# nrf9230_engb_application register map
Vendor: Nordic Semiconductor; Series: nRF92; File version: 1
CPU: CM33 r0p4, little endian, MPU, FPU, 3 interrupt priority bits, 480 interrupts, 4 SAU regions
Registers are 32-bit, read-write, reset 0x0 unless marked. A register's access mark holds for its fields unless they carry their own. Offsets are from the block's base; [hi:lo] are bit positions; lines under a group give offsets from that group; 'fields as' and 'values as' point back to an identical list.

## GLOBAL_TDDCONF_NS — TDDCONF 0
Base 0xBF001000
Same registers: GLOBAL_TDDCONF_S 0xBF001000 (alternate view of GLOBAL_TDDCONF_NS)
0x400 SYSPWRUPREQ — System power-up request
  [0] ACTIVE — Activate power-up request
    0=NotActive (Power-up request not active); 1=Active (Power-up request active)
0x404 DBGPWRUPREQ — Debug power-up request
  fields as SYSPWRUPREQ
0x408 TRACEPORTSPEED — Trace port trace clock speed
  [1:0] SPEED — Trace clock speed
    0=Speed100MHz; 1=Speed50MHz; 2=Speed25MHz; 3=Speed12500KHz (Speed 12.5MHz)
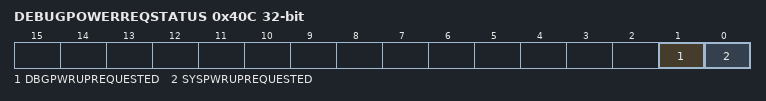
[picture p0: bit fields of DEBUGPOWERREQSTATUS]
0x40C DEBUGPOWERREQSTATUS ro — Combined effective system status of both SWJ-DP and TDDCONF registers originated power requests
  [1] DBGPWRUPREQUESTED — Debug domain powerup request status
    0=NoPowerReq (Power not requested); 1=Power requested
  [0] SYSPWRUPREQUESTED — System powerup request status
    0=NoPowerReq (Power not requested); 1=Power requested

## CPUC_S — CM33 SubSystem
Base 0xE0080000
0x100 EVENTS_FPUIOC — An invalid operation exception has occurred in the FPU.
  [0] EVENTS_FPUIOC
    0=NotGenerated (Event not generated); 1=Generated (Event generated)
0x104 EVENTS_FPUDZC — A floating-point divide-by-zero exception has occurred in the FPU.
  [0] EVENTS_FPUDZC
    values as EVENTS_FPUIOC.EVENTS_FPUIOC
0x108 EVENTS_FPUOFC — A floating-point overflow exception has occurred in the FPU.
  [0] EVENTS_FPUOFC
    values as EVENTS_FPUIOC.EVENTS_FPUIOC
0x10C EVENTS_FPUUFC — A floating-point underflow exception has occurred in the FPU.
  [0] EVENTS_FPUUFC
    values as EVENTS_FPUIOC.EVENTS_FPUIOC
0x110 EVENTS_FPUIXC — A floating-point inexact exception has occurred in the FPU.
  [0] EVENTS_FPUIXC
    values as EVENTS_FPUIOC.EVENTS_FPUIOC
0x114 EVENTS_FPUIDC — A floating-point input denormal exception has occurred in the FPU.
  [0] EVENTS_FPUIDC
    values as EVENTS_FPUIOC.EVENTS_FPUIOC
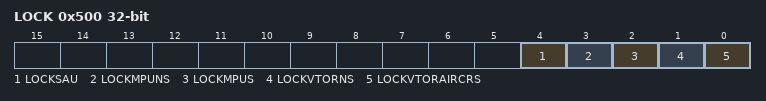
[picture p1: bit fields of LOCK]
0x500 LOCK — Register to lock the certain parts of the CPU from being modified.
  [4] LOCKSAU — Locks the Security Attribution Unit (SAU)
    0=NotLocked (SAU registers can be changed.); 1=Locked (Prevents changes to SAU registers.)
  [3] LOCKMPUNS — Locks the Memory Protection Unit (MPU) for non secure mode.
    0=NotLocked (MPU registers can be changed.); 1=Locked (Prevents changes to MPU registers.)
  [2] LOCKMPUS — Locks the Memory Protection Unit (MPU) for secure mode.
    values as LOCKMPUNS
  [1] LOCKVTORNS — Locks the Vector table Offset Register (VTOR) for non-secure mode.
    0=NotLocked (VTOR can be changed.); 1=Locked (Prevents changes to VTOR.)
  [0] LOCKVTORAIRCRS — Locks both the Vector table Offset Register (VTOR) and Application Interrupt and Reset Control Register (AIRCR) for secure mode.
    0=NotLocked (Both VTOR and AIRCR can be changed.); 1=Locked (Prevents changes to both VTOR and AIRCR.)
0x504 CPUID ro — The identifier for the CPU in this subsystem.
  [31:0] CPUID — The CPU identifier.

## ICACHE_S — Cache 0
Base 0xE0082000
Same registers: DCACHE_S 0xE0083000
0x00 TASKS_SAVE wo — Save the cache state to a retained memory space.
  [0] TASKS_SAVE
    1=Trigger task
0x04 TASKS_RESTORE wo — Restore the cache state from a retained memory space.
  [0] TASKS_RESTORE
    1=Trigger task
0x08 TASKS_INVALIDATECACHE wo — Invalidate the cache.
  [0] TASKS_INVALIDATECACHE
    1=Trigger task
0x0C TASKS_CLEANCACHE wo — Clean the cache.
  [0] TASKS_CLEANCACHE
    1=Trigger task
0x10 TASKS_FLUSHCACHE wo — Flush the cache.
  [0] TASKS_FLUSHCACHE
    1=Trigger task
0x14 TASKS_INVALIDATELINE wo — Invalidate the line.
  [0] TASKS_INVALIDATELINE
    1=Trigger task
0x18 TASKS_CLEANLINE wo — Clean the line.
  [0] TASKS_CLEANLINE
    1=Trigger task
0x1C TASKS_FLUSHLINE wo — Flush the line.
  [0] TASKS_FLUSHLINE
    1=Trigger task
0x20 TASKS_ERASE wo — Erase the cache.
  [0] TASKS_ERASE
    1=Trigger task
0x100 EVENTS_DONE — Save or Restore task is done.
  [0] EVENTS_DONE
    0=NotGenerated (Event not generated); 1=Generated (Event generated)
0x300 INTEN — Enable or disable interrupt
  [0] DONE — Enable or disable interrupt for event DONE
    0=Disabled; 1=Enabled
0x304 INTENSET — Enable interrupt
  [0] DONE — Write '1' to enable interrupt for event DONE
    on read: 0=Disabled (Read: Disabled); 1=Enabled (Read: Enabled) | on write: 1=Set (Enable)
0x308 INTENCLR — Disable interrupt
  [0] DONE — Write '1' to disable interrupt for event DONE
    on read: 0=Disabled (Read: Disabled); 1=Enabled (Read: Enabled) | on write: 1=Clear (Disable)
0x30C INTPEND ro — Pending interrupts
  [0] DONE — Read pending status of interrupt for event DONE
    on read: 0=NotPending (Read: Not pending); 1=Pending (Read: Pending)
0x400 STATUS ro — Status of the cache activities.
  [0] BUSY — Busy status.
    0=Ready (Activity is done and ready for the next activity.); 1=Busy (Activity is in progress.)
0x404 ENABLE — Enable cache.
  [0] ENABLE — Enable cache
    0=Disabled (Disable cache); 1=Enabled (Enable cache)
0x410 LINEADDR — Memory address covered by the line to be maintained.
  [31:0] ADDR — Address.
0x414 PROFILING group — Unspecified
  0x00 ENABLE — Enable the profiling counters.
    [0] ENABLE — Enable the profiling counters
      0=Disable profiling; 1=Enable profiling
  0x04 CLEAR wo — Clear the profiling counters.
    [0] CLEAR — Clearing the profiling counters
      1=Clear the profiling counters
  0x08 HIT ro — The cache hit counter for cache region.
    [31:0] HITS — Number of cache hits
  0x0C MISS ro — The cache miss counter for cache region.
    [31:0] MISSES — Number of cache misses
  0x10 LMISS ro — The cache line miss counter for cache region.
    [31:0] LMISSES — Number of cache line misses
  0x14 READS ro — Number of reads for cache region.
  0x18 WRITES ro — Number of writes for cache region.
0x430 DEBUGLOCK rw-once — Lock debug mode.
  [0] DEBUGLOCK — Lock debug mode
    0=Unlocked (Debug mode unlocked); 1=Locked (Debug mode locked. Ignores any other value written.)
0x434 WRITELOCK — Lock cache updates.
  [0] WRITELOCK — Lock cache updates
    0=Unlocked (Cache updates unlocked); 1=Locked (Cache updates locked)
